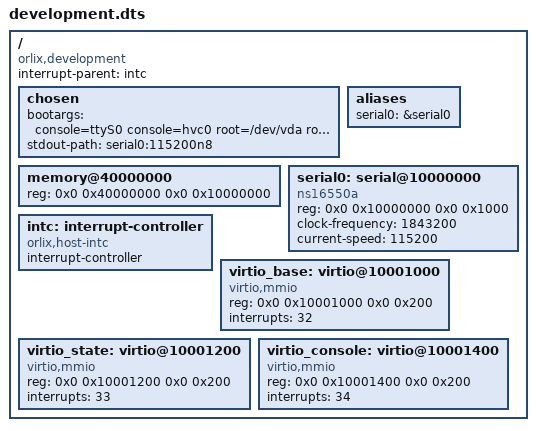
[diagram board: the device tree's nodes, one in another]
/dts-v1/;

/ {
	compatible = "orlix,development", "orlix";
	#address-cells = <2>;
	#size-cells = <2>;
	interrupt-parent = <&intc>;

	chosen {
		bootargs = "console=ttyS0 console=hvc0 root=/dev/vda rootfstype=ext4 ro debug ignore_loglevel orlix.profile=development";
		stdout-path = "serial0:115200n8";
	};

	memory@40000000 {
		device_type = "memory";
		reg = <0x0 0x40000000 0x0 0x10000000>;
	};

	aliases {
		serial0 = &serial0;
	};

	serial0: serial@10000000 {
		compatible = "ns16550a";
		reg = <0x0 0x10000000 0x0 0x1000>;
		clock-frequency = <1843200>;
		current-speed = <115200>;
		status = "okay";
	};

	intc: interrupt-controller {
		compatible = "orlix,host-intc";
		interrupt-controller;
		#address-cells = <0>;
		#interrupt-cells = <1>;
	};

	virtio_base: virtio@10001000 {
		compatible = "virtio,mmio";
		reg = <0x0 0x10001000 0x0 0x200>;
		interrupts = <32>;
		status = "okay";
	};

	virtio_state: virtio@10001200 {
		compatible = "virtio,mmio";
		reg = <0x0 0x10001200 0x0 0x200>;
		interrupts = <33>;
		status = "okay";
	};

	virtio_console: virtio@10001400 {
		compatible = "virtio,mmio";
		reg = <0x0 0x10001400 0x0 0x200>;
		interrupts = <34>;
		status = "okay";
	};
};
